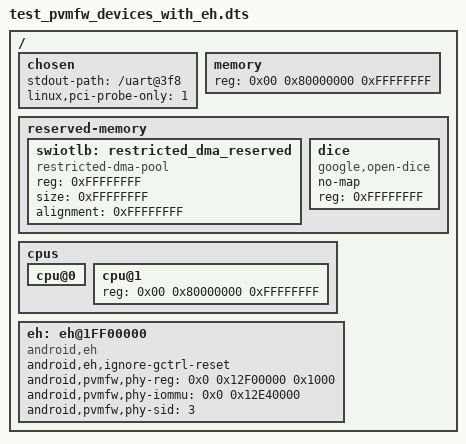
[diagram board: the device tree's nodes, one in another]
/dts-v1/;
/plugin/;

/ {
	chosen {
		stdout-path = "/uart@3f8";
		linux,pci-probe-only = <1>;
	};

	memory {
		device_type = "memory";
		reg = <0x00 0x80000000 0xFFFFFFFF>;
	};

	reserved-memory {
		#address-cells = <2>;
		#size-cells = <2>;
		ranges;
		swiotlb: restricted_dma_reserved {
			compatible = "restricted-dma-pool";
			reg = <0xFFFFFFFF>;
			size = <0xFFFFFFFF>;
			alignment = <0xFFFFFFFF>;
		};

		dice {
			compatible = "google,open-dice";
			no-map;
			reg = <0xFFFFFFFF>;
		};
	};

	cpus {
		#address-cells = <1>;
		#size-cells = <0>;
		cpu@0 {
			device_type = "cpu";
		};
		cpu@1 {
			device_type = "cpu";
		    reg = <0x00 0x80000000 0xFFFFFFFF>;
		};
    }

    eh: eh@1FF00000 {
        compatible = "android,eh";
        android,eh,ignore-gctrl-reset;
        android,pvmfw,phy-reg = <0x0 0x12F00000 0x1000>;
        android,pvmfw,phy-iommu = <0x0 0x12E40000>;
        android,pvmfw,phy-sid = <3>;
    };
};
